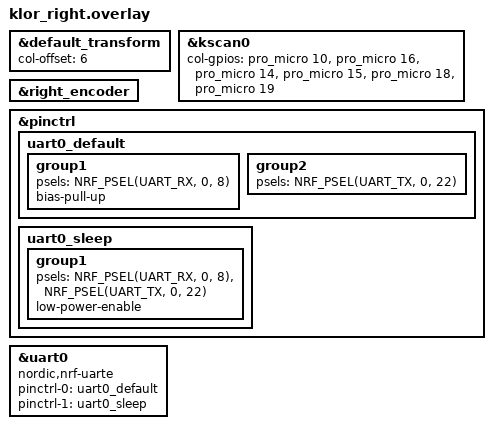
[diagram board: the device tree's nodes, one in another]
/*
* Copyright (c) 2022 GEIST
*
* SPDX-License-Identifier: MIT
*/

#include "klor.dtsi"

&default_transform {
  col-offset = <6>;
};

&kscan0 {
  col-gpios
    = <&pro_micro 10 GPIO_ACTIVE_HIGH>
    , <&pro_micro 16 GPIO_ACTIVE_HIGH>
    , <&pro_micro 14 GPIO_ACTIVE_HIGH>
    , <&pro_micro 15 GPIO_ACTIVE_HIGH>
    , <&pro_micro 18 GPIO_ACTIVE_HIGH>
    , <&pro_micro 19 GPIO_ACTIVE_HIGH>
    ;
};

&right_encoder {
  status = "okay";
};

&pinctrl {
  uart0_default: uart0_default {
    group1 {
      psels = <NRF_PSEL(UART_RX, 0, 8)>;
      bias-pull-up;
    };
    group2 {
      psels = <NRF_PSEL(UART_TX, 0, 22)>;
    };
  };

  uart0_sleep: uart0_sleep {
    group1 {
      psels = <NRF_PSEL(UART_RX, 0, 8)>,
        <NRF_PSEL(UART_TX, 0, 22)>;
      low-power-enable;
    };
  };
};

&uart0 {
  compatible = "nordic,nrf-uarte";
  pinctrl-0 = <&uart0_default>;
  pinctrl-1 = <&uart0_sleep>;
  pinctrl-names = "default", "sleep";
  status = "okay";
};
